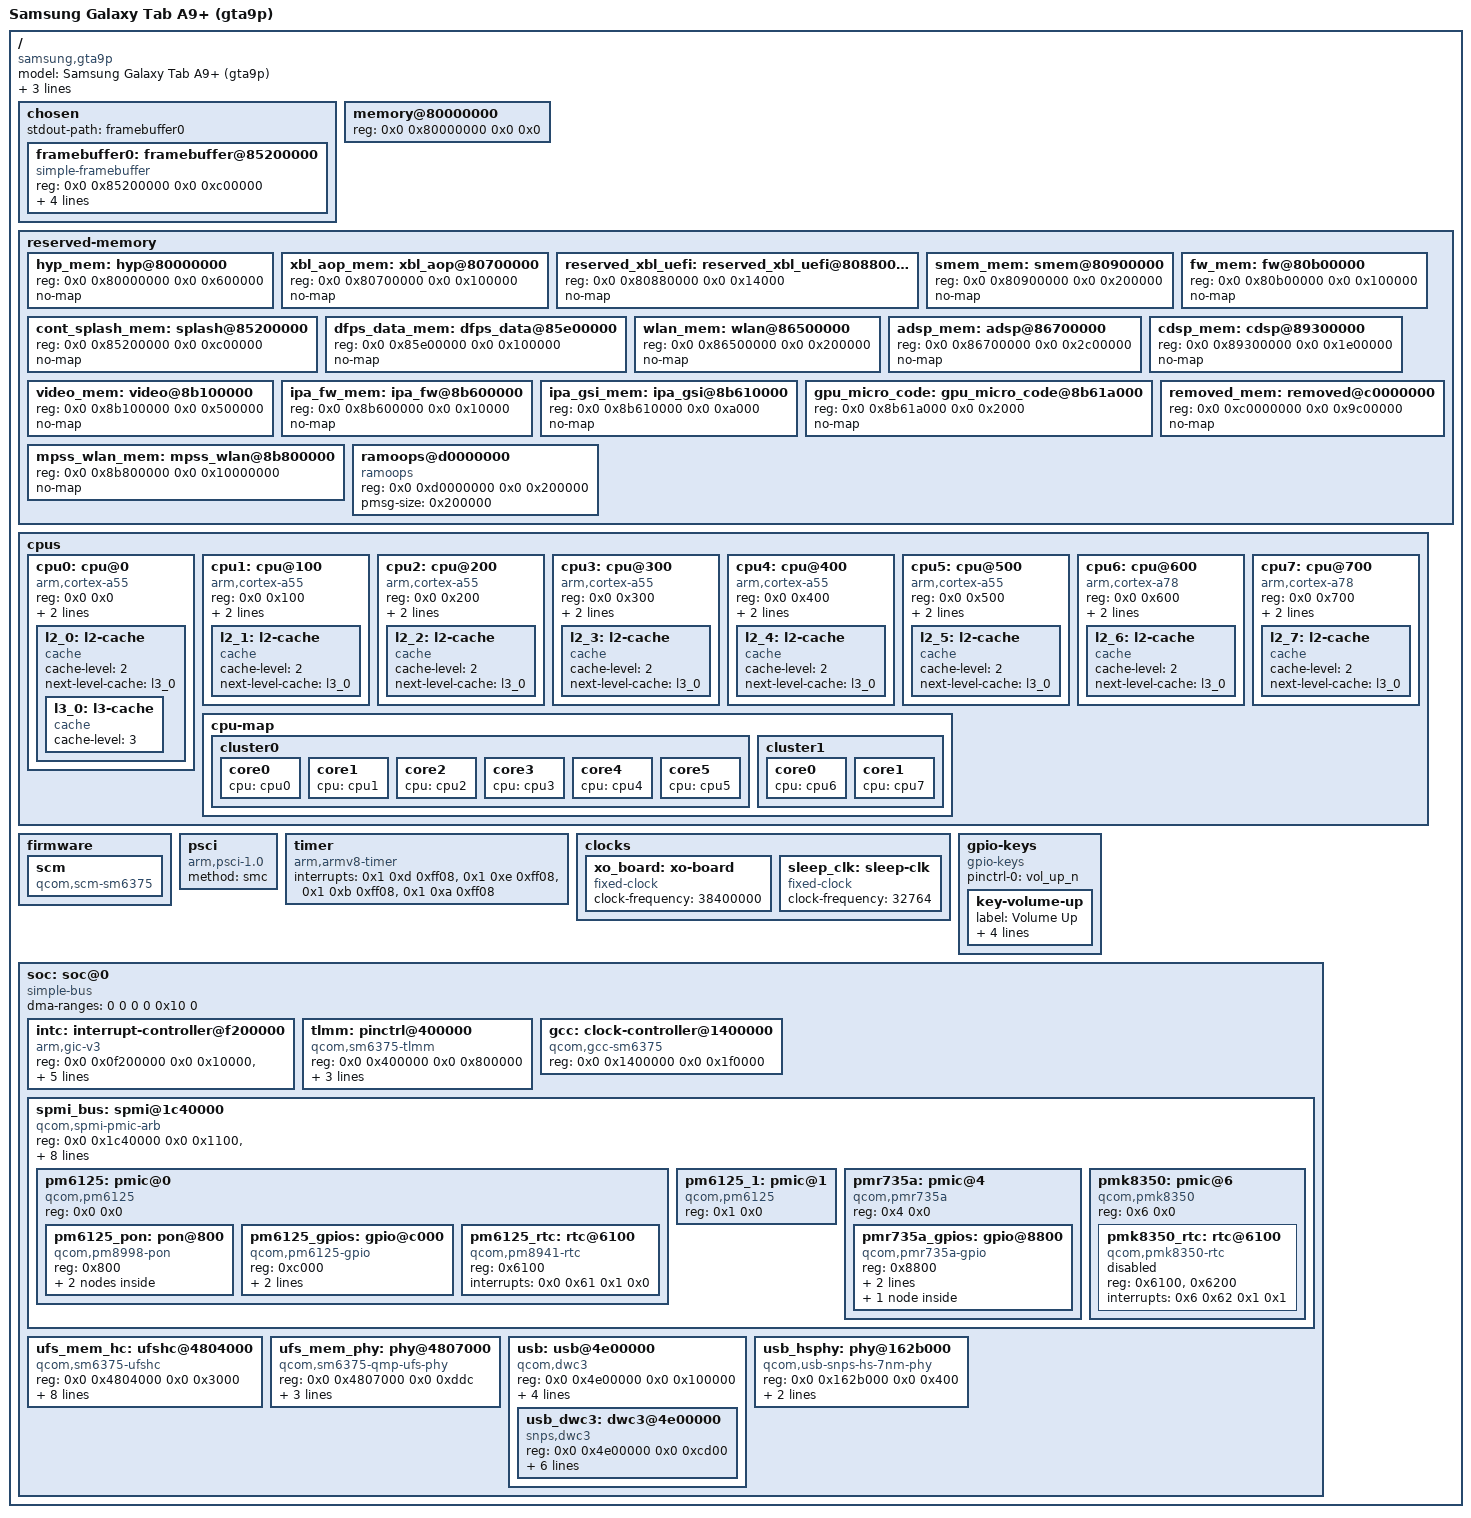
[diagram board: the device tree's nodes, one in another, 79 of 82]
/dts-v1/;

/ {
	model = "Samsung Galaxy Tab A9+ (gta9p)";
	compatible = "samsung,gta9p", "qcom,sm6375";
	qcom,msm-id = <0x1fb 0x10000>, <0x242 0x10000>;
	qcom,board-id = <0x1000b 0x0>;

	interrupt-parent = <&intc>;
	#address-cells = <2>;
	#size-cells = <2>;

	chosen {
		#address-cells = <2>;
		#size-cells = <2>;
		ranges;

		stdout-path = "framebuffer0";

		framebuffer0: framebuffer@85200000 {
			compatible = "simple-framebuffer";
			reg = <0x0 0x85200000 0x0 0xc00000>;
			width = <3600>;
			height = <1920>;
			stride = <4320>;
			format = "a8r8g8b8";
			status = "okay";
		};
	};

	memory@80000000 {
		device_type = "memory";
		reg = <0x0 0x80000000 0x0 0x0>;
	};

	reserved-memory {
		#address-cells = <2>;
		#size-cells = <2>;
		ranges;

		hyp_mem: hyp@80000000 {
			reg = <0x0 0x80000000 0x0 0x600000>;
			no-map;
		};

		xbl_aop_mem: xbl_aop@80700000 {
			reg = <0x0 0x80700000 0x0 0x100000>;
			no-map;
		};

		reserved_xbl_uefi: reserved_xbl_uefi@80880000 {
			reg = <0x0 0x80880000 0x0 0x14000>;
			no-map;
		};

		smem_mem: smem@80900000 {
			reg = <0x0 0x80900000 0x0 0x200000>;
			no-map;
		};

		fw_mem: fw@80b00000 {
			reg = <0x0 0x80b00000 0x0 0x100000>;
			no-map;
		};

		cont_splash_mem: splash@85200000 {
			reg = <0x0 0x85200000 0x0 0xc00000>;
			no-map;
		};

		dfps_data_mem: dfps_data@85e00000 {
			reg = <0x0 0x85e00000 0x0 0x100000>;
			no-map;
		};

		wlan_mem: wlan@86500000 {
			reg = <0x0 0x86500000 0x0 0x200000>;
			no-map;
		};

		adsp_mem: adsp@86700000 {
			reg = <0x0 0x86700000 0x0 0x2c00000>;
			no-map;
		};

		cdsp_mem: cdsp@89300000 {
			reg = <0x0 0x89300000 0x0 0x1e00000>;
			no-map;
		};

		video_mem: video@8b100000 {
			reg = <0x0 0x8b100000 0x0 0x500000>;
			no-map;
		};

		ipa_fw_mem: ipa_fw@8b600000 {
			reg = <0x0 0x8b600000 0x0 0x10000>;
			no-map;
		};

		ipa_gsi_mem: ipa_gsi@8b610000 {
			reg = <0x0 0x8b610000 0x0 0xa000>;
			no-map;
		};

		gpu_micro_code: gpu_micro_code@8b61a000 {
			reg = <0x0 0x8b61a000 0x0 0x2000>;
			no-map;
		};

		mpss_wlan_mem: mpss_wlan@8b800000 {
			reg = <0x0 0x8b800000 0x0 0x10000000>;
			no-map;
		};

		removed_mem: removed@c0000000 {
			reg = <0x0 0xc0000000 0x0 0x9c00000>;
			no-map;
		};

		ramoops@d0000000 {
			compatible = "ramoops";
			reg = <0x0 0xd0000000 0x0 0x200000>;
			pmsg-size = <0x200000>;
		};
	};

	cpus {
		#address-cells = <2>;
		#size-cells = <0>;

		cpu0: cpu@0 {
			device_type = "cpu";
			compatible = "arm,cortex-a55";
			reg = <0x0 0x0>;
			enable-method = "psci";
			next-level-cache = <&l2_0>;

			l2_0: l2-cache {
				compatible = "cache";
				cache-level = <2>;
				next-level-cache = <&l3_0>;

				l3_0: l3-cache {
					compatible = "cache";
					cache-level = <3>;
				};
			};
		};

		cpu1: cpu@100 {
			device_type = "cpu";
			compatible = "arm,cortex-a55";
			reg = <0x0 0x100>;
			enable-method = "psci";
			next-level-cache = <&l2_1>;

			l2_1: l2-cache {
				compatible = "cache";
				cache-level = <2>;
				next-level-cache = <&l3_0>;
			};
		};

		cpu2: cpu@200 {
			device_type = "cpu";
			compatible = "arm,cortex-a55";
			reg = <0x0 0x200>;
			enable-method = "psci";
			next-level-cache = <&l2_2>;

			l2_2: l2-cache {
				compatible = "cache";
				cache-level = <2>;
				next-level-cache = <&l3_0>;
			};
		};

		cpu3: cpu@300 {
			device_type = "cpu";
			compatible = "arm,cortex-a55";
			reg = <0x0 0x300>;
			enable-method = "psci";
			next-level-cache = <&l2_3>;

			l2_3: l2-cache {
				compatible = "cache";
				cache-level = <2>;
				next-level-cache = <&l3_0>;
			};
		};

		cpu4: cpu@400 {
			device_type = "cpu";
			compatible = "arm,cortex-a55";
			reg = <0x0 0x400>;
			enable-method = "psci";
			next-level-cache = <&l2_4>;

			l2_4: l2-cache {
				compatible = "cache";
				cache-level = <2>;
				next-level-cache = <&l3_0>;
			};
		};

		cpu5: cpu@500 {
			device_type = "cpu";
			compatible = "arm,cortex-a55";
			reg = <0x0 0x500>;
			enable-method = "psci";
			next-level-cache = <&l2_5>;

			l2_5: l2-cache {
				compatible = "cache";
				cache-level = <2>;
				next-level-cache = <&l3_0>;
			};
		};

		cpu6: cpu@600 {
			device_type = "cpu";
			compatible = "arm,cortex-a78";
			reg = <0x0 0x600>;
			enable-method = "psci";
			next-level-cache = <&l2_6>;

			l2_6: l2-cache {
				compatible = "cache";
				cache-level = <2>;
				next-level-cache = <&l3_0>;
			};
		};

		cpu7: cpu@700 {
			device_type = "cpu";
			compatible = "arm,cortex-a78";
			reg = <0x0 0x700>;
			enable-method = "psci";
			next-level-cache = <&l2_7>;

			l2_7: l2-cache {
				compatible = "cache";
				cache-level = <2>;
				next-level-cache = <&l3_0>;
			};
		};

		cpu-map {
			cluster0 {
				core0 { cpu = <&cpu0>; };
				core1 { cpu = <&cpu1>; };
				core2 { cpu = <&cpu2>; };
				core3 { cpu = <&cpu3>; };
				core4 { cpu = <&cpu4>; };
				core5 { cpu = <&cpu5>; };
			};

			cluster1 {
				core0 { cpu = <&cpu6>; };
				core1 { cpu = <&cpu7>; };
			};
		};
	};

	firmware {
		scm {
			compatible = "qcom,scm-sm6375", "qcom,scm";
		};
	};

	psci {
		compatible = "arm,psci-1.0";
		method = "smc";
	};

	timer {
		compatible = "arm,armv8-timer";
		interrupts = <0x1 0xd 0xff08>,
			     <0x1 0xe 0xff08>,
			     <0x1 0xb 0xff08>,
			     <0x1 0xa 0xff08>;
	};

	clocks {
		xo_board: xo-board {
			compatible = "fixed-clock";
			clock-frequency = <38400000>;
			#clock-cells = <0>;
		};

		sleep_clk: sleep-clk {
			compatible = "fixed-clock";
			clock-frequency = <32764>;
			#clock-cells = <0>;
		};
	};

	gpio-keys {
		compatible = "gpio-keys";
		pinctrl-names = "default";
		pinctrl-0 = <&vol_up_n>;

		key-volume-up {
			label = "Volume Up";
			linux,code = <115>;
			gpios = <&pmr735a_gpios 1 1>;
			debounce-interval = <15>;
			linux,can-disable;
		};
	};

	soc: soc@0 {
		compatible = "simple-bus";
		#address-cells = <2>;
		#size-cells = <2>;
		ranges = <0 0 0 0 0x10 0>;
		dma-ranges = <0 0 0 0 0x10 0>;

		intc: interrupt-controller@f200000 {
			compatible = "arm,gic-v3";
			reg = <0x0 0x0f200000 0x0 0x10000>,
			      <0x0 0x0f240000 0x0 0x100000>;
			#interrupt-cells = <3>;
			interrupt-controller;
			#redistributor-regions = <1>;
			redistributor-stride = <0x0 0x20000>;
			interrupts = <0x1 0x8 0x4>;
		};

		tlmm: pinctrl@400000 {
			compatible = "qcom,sm6375-tlmm";
			reg = <0x0 0x400000 0x0 0x800000>;
			interrupts = <0x0 0xe3 0x4>;
			gpio-controller;
			#gpio-cells = <2>;
			interrupt-controller;
			#interrupt-cells = <2>;
		};

		gcc: clock-controller@1400000 {
			compatible = "qcom,gcc-sm6375";
			reg = <0x0 0x1400000 0x0 0x1f0000>;
			#clock-cells = <1>;
			#reset-cells = <1>;
			#power-domain-cells = <1>;
		};

		spmi_bus: spmi@1c40000 {
			compatible = "qcom,spmi-pmic-arb";
			reg = <0x0 0x1c40000 0x0 0x1100>,
			      <0x0 0x1e00000 0x0 0x2000000>,
			      <0x0 0x3e00000 0x0 0x100000>,
			      <0x0 0x3f00000 0x0 0xa0000>,
			      <0x0 0x1c0a000 0x0 0x26000>;
			reg-names = "core", "chnls", "obsrvr", "intr", "cnfg";
			interrupt-names = "periph_irq";
			interrupts = <0x0 0x56 0x4>;
			qcom,ee = <0>;
			qcom,channel = <0>;
			#address-cells = <2>;
			#size-cells = <0>;
			interrupt-controller;
			#interrupt-cells = <4>;

			pm6125: pmic@0 {
				compatible = "qcom,pm6125", "qcom,spmi-pmic";
				reg = <0x0 0x0>;
				#address-cells = <1>;
				#size-cells = <0>;

				pm6125_pon: pon@800 {
					compatible = "qcom,pm8998-pon";
					reg = <0x800>;

					pm6125_pwrkey: pwrkey {
						compatible = "qcom,pm8941-pwrkey";
						interrupts = <0x0 0x8 0x0 0x3>;
						debounce = <15625>;
						bias-pull-up;
						linux,code = <116>;
					};

					pm6125_resin: resin {
						compatible = "qcom,pm8941-resin";
						interrupts = <0x0 0x8 0x1 0x3>;
						debounce = <15625>;
						bias-pull-up;
						linux,code = <114>;
					};
				};

				pm6125_gpios: gpio@c000 {
					compatible = "qcom,pm6125-gpio", "qcom,spmi-gpio";
					reg = <0xc000>;
					gpio-controller;
					#gpio-cells = <2>;
					interrupt-controller;
					#interrupt-cells = <2>;
				};

				pm6125_rtc: rtc@6100 {
					compatible = "qcom,pm8941-rtc";
					reg = <0x6100>;
					interrupts = <0x0 0x61 0x1 0x0>;
				};
			};

			pm6125_1: pmic@1 {
				compatible = "qcom,pm6125", "qcom,spmi-pmic";
				reg = <0x1 0x0>;
				#address-cells = <1>;
				#size-cells = <0>;
			};

			pmr735a: pmic@4 {
				compatible = "qcom,pmr735a", "qcom,spmi-pmic";
				reg = <0x4 0x0>;
				#address-cells = <1>;
				#size-cells = <0>;

				pmr735a_gpios: gpio@8800 {
					compatible = "qcom,pmr735a-gpio", "qcom,spmi-gpio";
					reg = <0x8800>;
					gpio-controller;
					#gpio-cells = <2>;
					interrupt-controller;
					#interrupt-cells = <2>;

					vol_up_n: vol-up-n-state {
						pins = "gpio1";
						function = "normal";
						input-enable;
						bias-pull-up;
						power-source = <1>;
					};
				};
			};

			pmk8350: pmic@6 {
				compatible = "qcom,pmk8350", "qcom,spmi-pmic";
				reg = <0x6 0x0>;
				#address-cells = <1>;
				#size-cells = <0>;

				pmk8350_rtc: rtc@6100 {
					compatible = "qcom,pmk8350-rtc";
					reg = <0x6100>, <0x6200>;
					reg-names = "rtc", "alarm";
					interrupts = <0x6 0x62 0x1 0x1>;
					status = "disabled";
				};
			};
		};

		ufs_mem_hc: ufshc@4804000 {
			compatible = "qcom,sm6375-ufshc", "qcom,ufshc", "jedec,ufs-2.0";
			reg = <0x0 0x4804000 0x0 0x3000>;
			interrupts = <0x0 0x164 0x4>;
			phys = <&ufs_mem_phy>;
			phy-names = "ufsphy";
			lanes-per-direction = <1>;
			resets = <&gcc 13>;
			reset-names = "rst";
			clocks = <&gcc 158>,
				 <&gcc 154>,
				 <&gcc 157>,
				 <&gcc 166>,
				 <&gcc 160>,
				 <&xo_board>,
				 <&gcc 165>,
				 <&gcc 164>;
			clock-names = "core_clk",
				      "bus_aggr_clk",
				      "iface_clk",
				      "core_clk_unipro",
				      "ice_core_clk",
				      "ref_clk",
				      "tx_lane0_sync_clk",
				      "rx_lane0_sync_clk";
			reset-gpios = <&tlmm 156 1>;
			power-domains = <&gcc 1>;
			status = "okay";
		};

		ufs_mem_phy: phy@4807000 {
			compatible = "qcom,sm6375-qmp-ufs-phy";
			reg = <0x0 0x4807000 0x0 0xddc>;
			#phy-cells = <0>;
			clocks = <&gcc 156>,
				 <&gcc 162>;
			clock-names = "ref", "ref_aux";
			resets = <&gcc 13>;
			reset-names = "ufsphy";
			power-domains = <&gcc 1>;
			status = "okay";
		};

		usb: usb@4e00000 {
			compatible = "qcom,dwc3";
			reg = <0x0 0x4e00000 0x0 0x100000>;
			#address-cells = <2>;
			#size-cells = <2>;
			ranges;
			clocks = <&gcc 168>,
				 <&gcc 79>,
				 <&gcc 170>,
				 <&gcc 173>;
			clock-names = "core", "iface", "mock_utmi", "sleep";
			resets = <&gcc 14>;
			reset-names = "core";
			power-domains = <&gcc 0>;
			qcom,select-utmi-as-pipe-clk;
			status = "okay";

			usb_dwc3: dwc3@4e00000 {
				compatible = "snps,dwc3";
				reg = <0x0 0x4e00000 0x0 0xcd00>;
				interrupts = <0x0 0xff 0x4>;
				phys = <&usb_hsphy>;
				phy-names = "usb2-phy";
				maximum-speed = "high-speed";
				dr_mode = "peripheral";
				snps,dis_u2_susphy_quirk;
				snps,dis_enblslpm_quirk;
			};
		};

		usb_hsphy: phy@162b000 {
			compatible = "qcom,usb-snps-hs-7nm-phy";
			reg = <0x0 0x162b000 0x0 0x400>;
			#phy-cells = <0>;
			clocks = <&xo_board>;
			clock-names = "ref";
			resets = <&gcc 9>;
			reset-names = "phy";
			status = "okay";
		};
	};
};
